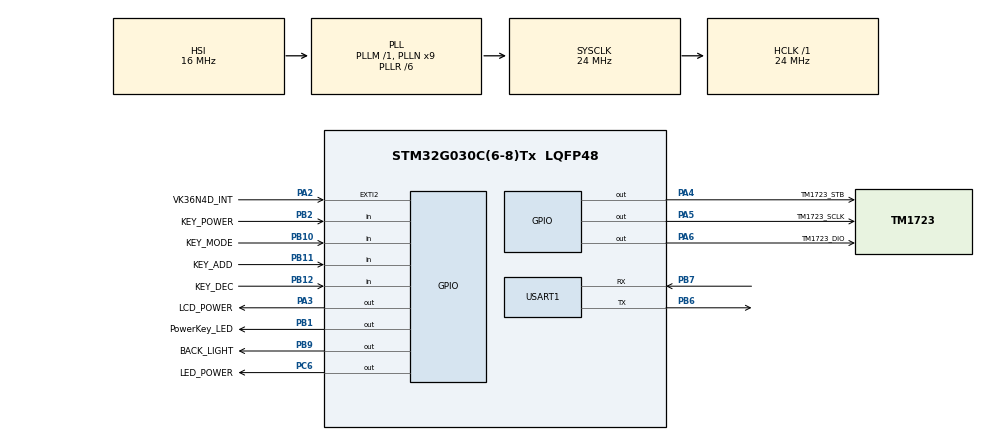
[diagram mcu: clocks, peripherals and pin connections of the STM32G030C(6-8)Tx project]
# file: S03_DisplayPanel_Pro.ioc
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Mcu.Family=STM32G0
Mcu.Name=STM32G030C(6-8)Tx
Mcu.Package=LQFP48
NVIC.EXTI2_3_IRQn=true\:0\:0\:false\:false\:true\:true\:true\:true
NVIC.TIM14_IRQn=true\:0\:0\:false\:false\:true\:true\:true\:true
NVIC.TIM3_IRQn=true\:0\:0\:false\:false\:true\:true\:true\:true
NVIC.USART1_IRQn=true\:0\:0\:false\:false\:true\:true\:true\:true
PA2.GPIO_Label=VK36N4D_INT
PA2.Signal=GPXTI2
PA3.GPIO_Label=LCD_POWER
PA3.Signal=GPIO_Output
PA4.GPIO_Label=TM1723_STB
PA4.Signal=GPIO_Output
PA5.GPIO_Label=TM1723_SCLK
PA5.Signal=GPIO_Output
PA6.GPIO_Label=TM1723_DIO
PA6.Signal=GPIO_Output
PB1.GPIO_Label=PowerKey_LED
PB1.Signal=GPIO_Output
PB10.GPIO_Label=KEY_MODE
PB10.Signal=GPIO_Input
PB11.GPIO_Label=KEY_ADD
PB11.Signal=GPIO_Input
PB12.GPIO_Label=KEY_DEC
PB12.Signal=GPIO_Input
PB2.GPIO_Label=KEY_POWER
PB2.Signal=GPIO_Input
PB6.Mode=Asynchronous
PB6.Signal=USART1_TX
PB7.Mode=Asynchronous
PB7.Signal=USART1_RX
PB9.GPIO_Label=BACK_LIGHT
PB9.Signal=GPIO_Output
PC6.GPIO_Label=LED_POWER
PC6.Signal=GPIO_Output
ProjectManager.HeapSize=0x200
ProjectManager.StackSize=0x400
ProjectManager.TargetToolchain=MDK-ARM V5.32
RCC.ADCFreq_Value=24000000
RCC.AHBFreq_Value=24000000
RCC.CortexFreq_Value=24000000
RCC.EXTERNAL_CLOCK_VALUE=12288000
RCC.HCLKFreq_Value=24000000
RCC.HSE_VALUE=8000000
RCC.HSI_VALUE=16000000
RCC.LSE_VALUE=32768
RCC.PLLN=9
RCC.PLLR=RCC_PLLR_DIV6
RCC.SYSCLKFreq_VALUE=24000000
RCC.SYSCLKSource=RCC_SYSCLKSOURCE_PLLCLK
RCC.VCOOutputFreq_Value=144000000
USART1.VirtualMode-Asynchronous=VM_ASYNC
VP_TIM14_VS_ClockSourceINT.Mode=Enable_Timer
VP_TIM3_VS_ClockSourceINT.Mode=Internal
board=custom

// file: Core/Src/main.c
/* USER CODE BEGIN Header */
/**
  ******************************************************************************
  * @file           : main.c
  * @brief          : Main program body
  ******************************************************************************
  * @attention
  *
  * Copyright (c) 2022 STMicroelectronics.
  * All rights reserved.
  *
  * This software is licensed under terms that can be found in the LICENSE file
  * in the root directory of this software component.
  * If no LICENSE file comes with this software, it is provided AS-IS.
  *
  ******************************************************************************
  */
/* USER CODE END Header */
#include "main.h"
#include "tim.h"
#include "usart.h"
#include "gpio.h"

/* USER CODE BEGIN Includes */
#include "lcd.h"
/* USER CODE END Includes */

void SystemClock_Config(void);

int main(void)
{

  /* MCU Configuration--------------------------------------------------------*/

  /* Reset of all peripherals, Initializes the Flash interface and the Systick. */
  HAL_Init();

  /* Configure the system clock */
  SystemClock_Config();

  /* Initialize all configured peripherals */
  MX_GPIO_Init();
  MX_TIM3_Init();
  MX_TIM14_Init();
  MX_USART1_UART_Init();
  /* USER CODE BEGIN 2 */
  HAL_TIM_Base_Start_IT(&htim3);
  HAL_TIM_Base_Start_IT(&htim14);
  /* USER CODE END 2 */

  /* Infinite loop */
  while (1)
  {

    /* USER CODE BEGIN 3 */
       TM1723_POWER_ON();
	LCD_BACK_LIGHT_ON()	;
    DisplayPanel_Handler();
  }
  /* USER CODE END 3 */
}

void SystemClock_Config(void)
{
  RCC_OscInitTypeDef RCC_OscInitStruct = {0};
  RCC_ClkInitTypeDef RCC_ClkInitStruct = {0};

  /** Configure the main internal regulator output voltage
  */
  HAL_PWREx_ControlVoltageScaling(PWR_REGULATOR_VOLTAGE_SCALE1);

  /** Initializes the RCC Oscillators according to the specified parameters
  * in the RCC_OscInitTypeDef structure.
  */
  RCC_OscInitStruct.OscillatorType = RCC_OSCILLATORTYPE_HSI;
  RCC_OscInitStruct.HSIState = RCC_HSI_ON;
  RCC_OscInitStruct.HSIDiv = RCC_HSI_DIV1;
  RCC_OscInitStruct.HSICalibrationValue = RCC_HSICALIBRATION_DEFAULT;
  RCC_OscInitStruct.PLL.PLLState = RCC_PLL_ON;
  RCC_OscInitStruct.PLL.PLLSource = RCC_PLLSOURCE_HSI;
  RCC_OscInitStruct.PLL.PLLM = RCC_PLLM_DIV1;
  RCC_OscInitStruct.PLL.PLLN = 9;
  RCC_OscInitStruct.PLL.PLLP = RCC_PLLP_DIV2;
  RCC_OscInitStruct.PLL.PLLR = RCC_PLLR_DIV6;
  if (HAL_RCC_OscConfig(&RCC_OscInitStruct) != HAL_OK)
  {
    Error_Handler();
  }

  /** Initializes the CPU, AHB and APB buses clocks
  */
  RCC_ClkInitStruct.ClockType = RCC_CLOCKTYPE_HCLK|RCC_CLOCKTYPE_SYSCLK
                              |RCC_CLOCKTYPE_PCLK1;
  RCC_ClkInitStruct.SYSCLKSource = RCC_SYSCLKSOURCE_PLLCLK;
  RCC_ClkInitStruct.AHBCLKDivider = RCC_SYSCLK_DIV1;
  RCC_ClkInitStruct.APB1CLKDivider = RCC_HCLK_DIV1;

  if (HAL_RCC_ClockConfig(&RCC_ClkInitStruct, FLASH_LATENCY_0) != HAL_OK)
  {
    Error_Handler();
  }
}

void Error_Handler(void)
{
  __disable_irq();
  while (1)
  {
  }
}
